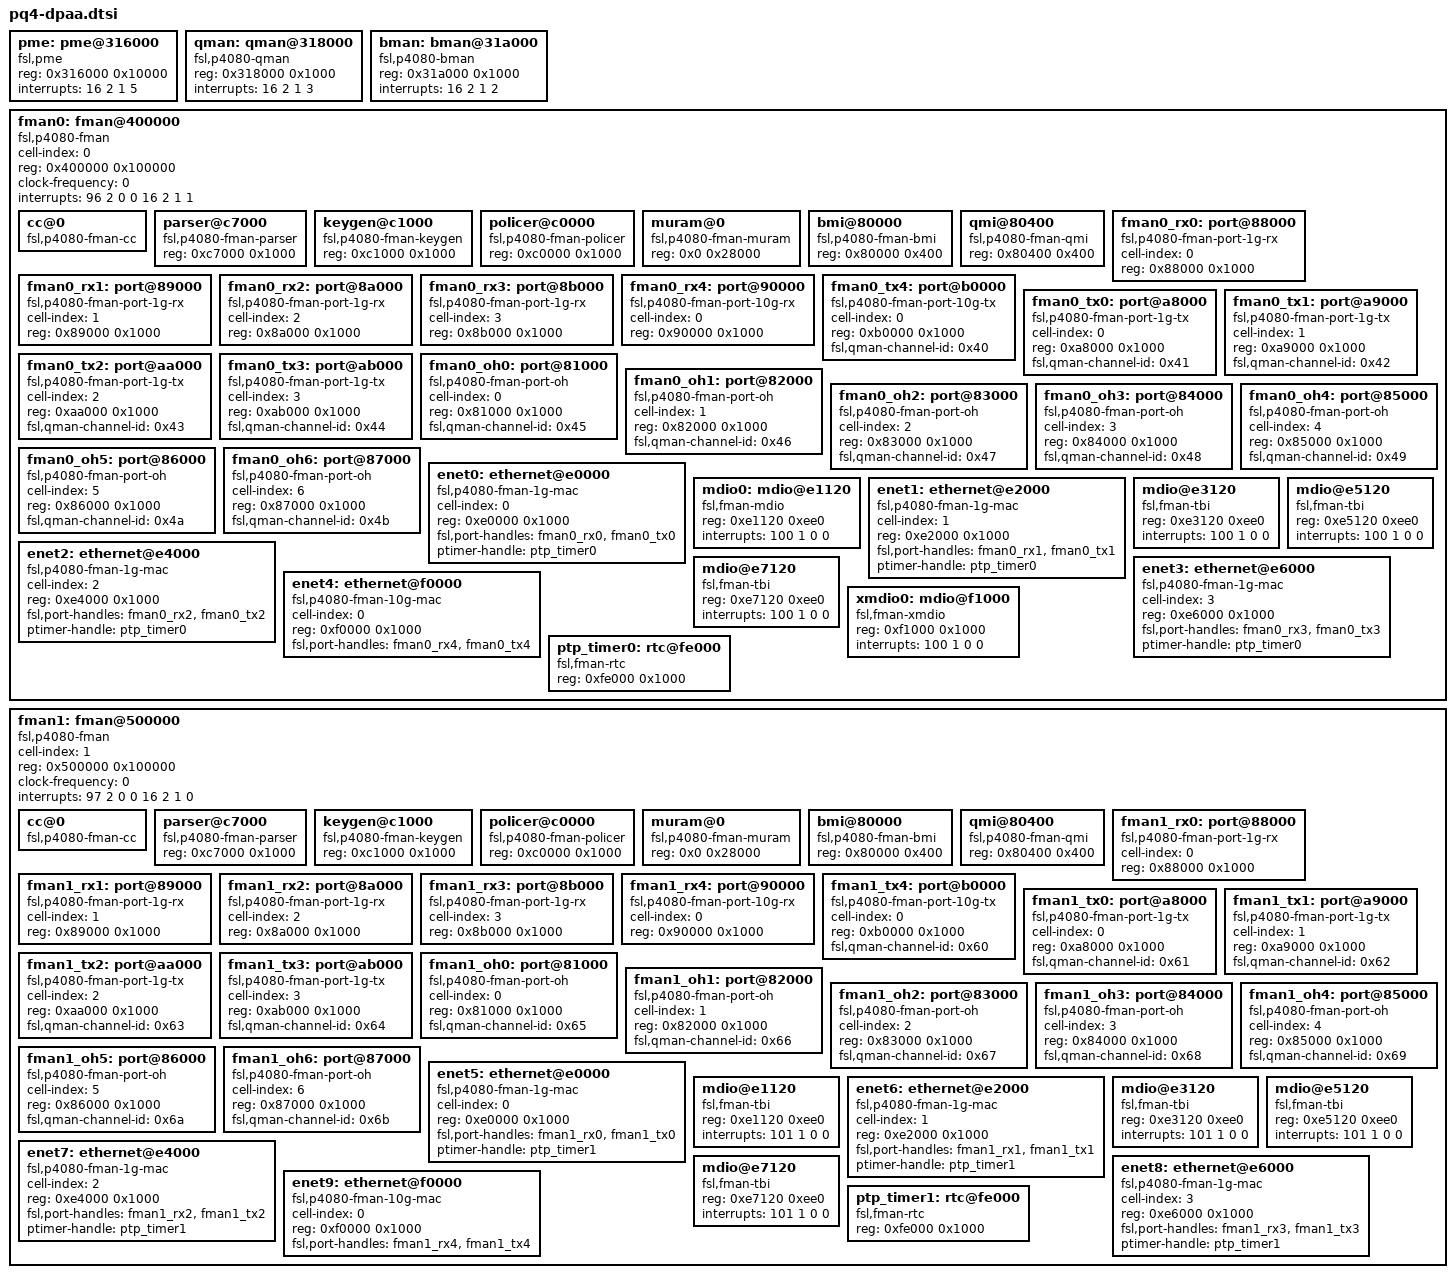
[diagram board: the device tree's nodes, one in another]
/*
 * P4 pme, qman, bman and famn Device Tree Source
 *
 * Copyright 2009-2011 Freescale Semiconductor Inc.
 *
 * Redistribution and use in source and binary forms, with or without
 * modification, are permitted provided that the following conditions are met:
 *     * Redistributions of source code must retain the above copyright
 *       notice, this list of conditions and the following disclaimer.
 *     * Redistributions in binary form must reproduce the above copyright
 *       notice, this list of conditions and the following disclaimer in the
 *       documentation and/or other materials provided with the distribution.
 *     * Neither the name of Freescale Semiconductor nor the
 *       names of its contributors may be used to endorse or promote products
 *       derived from this software without specific prior written permission.
 *
 *
 * ALTERNATIVELY, this software may be distributed under the terms of the
 * GNU General Public License ("GPL") as published by the Free Software
 * Foundation, either version 2 of that License or (at your option) any
 * later version.
 *
 * THIS SOFTWARE IS PROVIDED BY Freescale Semiconductor ``AS IS'' AND ANY
 * EXPRESS OR IMPLIED WARRANTIES, INCLUDING, BUT NOT LIMITED TO, THE IMPLIED
 * WARRANTIES OF MERCHANTABILITY AND FITNESS FOR A PARTICULAR PURPOSE ARE
 * DISCLAIMED. IN NO EVENT SHALL Freescale Semiconductor BE LIABLE FOR ANY
 * DIRECT, INDIRECT, INCIDENTAL, SPECIAL, EXEMPLARY, OR CONSEQUENTIAL DAMAGES
 * (INCLUDING, BUT NOT LIMITED TO, PROCUREMENT OF SUBSTITUTE GOODS OR SERVICES;
 * LOSS OF USE, DATA, OR PROFITS; OR BUSINESS INTERRUPTION) HOWEVER CAUSED AND
 * ON ANY THEORY OF LIABILITY, WHETHER IN CONTRACT, STRICT LIABILITY, OR TORT
 * (INCLUDING NEGLIGENCE OR OTHERWISE) ARISING IN ANY WAY OUT OF THE USE OF THIS
 * SOFTWARE, EVEN IF ADVISED OF THE POSSIBILITY OF SUCH DAMAGE.
 */

pme: pme@316000 {
	compatible = "fsl,pme";
	reg = <0x316000 0x10000>;
	/* fsl,pme-pdsr = <0x0 0x23000000 0x0 0x01000000>; */
	/* fsl,pme-sre = <0x0 0x24000000 0x0 0x00a00000>; */
	interrupts = <16 2 1 5>;
};

qman: qman@318000 {
	compatible = "fsl,p4080-qman", "fsl,qman";
	reg = <0x318000 0x1000>;
	interrupts = <16 2 1 3>;
	/* Commented out, use default allocation */
	/* fsl,qman-fqd = <0x0 0x20000000 0x0 0x01000000>; */
	/* fsl,qman-pfdr = <0x0 0x21000000 0x0 0x01000000>; */
};

bman: bman@31a000 {
	compatible = "fsl,p4080-bman", "fsl,bman";
	reg = <0x31a000 0x1000>;
	interrupts = <16 2 1 2>;
	/* Same as fsl,qman-*, use default allocation */
	/* fsl,bman-fbpr = <0x0 0x22000000 0x0 0x01000000>; */
};

fman0: fman@400000 {
	#address-cells = <1>;
	#size-cells = <1>;
	cell-index = <0>;
	compatible = "fsl,p4080-fman", "fsl,fman", "simple-bus";
	ranges = <0 0x400000 0x100000>;
	reg = <0x400000 0x100000>;
	clock-frequency = <0>;
	interrupts = <
		96 2 0 0
		16 2 1 1>;

	cc@0 {
		compatible = "fsl,p4080-fman-cc", "fsl,fman-cc";
	};

	parser@c7000 {
		compatible = "fsl,p4080-fman-parser", "fsl,fman-parser";
		reg = <0xc7000 0x1000>;
	};

	keygen@c1000 {
		compatible = "fsl,p4080-fman-keygen", "fsl,fman-keygen";
		reg = <0xc1000 0x1000>;
	};

	policer@c0000 {
		compatible = "fsl,p4080-fman-policer", "fsl,fman-policer";
		reg = <0xc0000 0x1000>;
	};

	muram@0 {
		compatible = "fsl,p4080-fman-muram", "fsl,fman-muram";
		reg = <0x0 0x28000>;
	};

	bmi@80000 {
		compatible = "fsl,p4080-fman-bmi", "fsl,fman-bmi";
		reg = <0x80000 0x400>;
	};

	qmi@80400 {
		compatible = "fsl,p4080-fman-qmi", "fsl,fman-qmi";
		reg = <0x80400 0x400>;
	};

	fman0_rx0: port@88000 {
		cell-index = <0>;
		compatible = "fsl,p4080-fman-port-1g-rx", "fsl,fman-port-1g-rx";
		reg = <0x88000 0x1000>;
	};
	fman0_rx1: port@89000 {
		cell-index = <1>;
		compatible = "fsl,p4080-fman-port-1g-rx", "fsl,fman-port-1g-rx";
		reg = <0x89000 0x1000>;
	};
	fman0_rx2: port@8a000 {
		cell-index = <2>;
		compatible = "fsl,p4080-fman-port-1g-rx", "fsl,fman-port-1g-rx";
		reg = <0x8a000 0x1000>;
	};
	fman0_rx3: port@8b000 {
		cell-index = <3>;
		compatible = "fsl,p4080-fman-port-1g-rx", "fsl,fman-port-1g-rx";
		reg = <0x8b000 0x1000>;
	};
	fman0_rx4: port@90000 {
		cell-index = <0>;
		compatible = "fsl,p4080-fman-port-10g-rx", "fsl,fman-port-10g-rx";
		reg = <0x90000 0x1000>;
	};

	fman0_tx4: port@b0000 {
		cell-index = <0>;
		compatible = "fsl,p4080-fman-port-10g-tx", "fsl,fman-port-10g-tx";
		reg = <0xb0000 0x1000>;
		fsl,qman-channel-id = <0x40>;
	};
	fman0_tx0: port@a8000 {
		cell-index = <0>;
		compatible = "fsl,p4080-fman-port-1g-tx", "fsl,fman-port-1g-tx";
		reg = <0xa8000 0x1000>;
		fsl,qman-channel-id = <0x41>;
	};
	fman0_tx1: port@a9000 {
		cell-index = <1>;
		compatible = "fsl,p4080-fman-port-1g-tx", "fsl,fman-port-1g-tx";
		reg = <0xa9000 0x1000>;
		fsl,qman-channel-id = <0x42>;
	};
	fman0_tx2: port@aa000 {
		cell-index = <2>;
		compatible = "fsl,p4080-fman-port-1g-tx", "fsl,fman-port-1g-tx";
		reg = <0xaa000 0x1000>;
		fsl,qman-channel-id = <0x43>;
	};
	fman0_tx3: port@ab000 {
		cell-index = <3>;
		compatible = "fsl,p4080-fman-port-1g-tx", "fsl,fman-port-1g-tx";
		reg = <0xab000 0x1000>;
		fsl,qman-channel-id = <0x44>;
	};

	fman0_oh0: port@81000 {
		cell-index = <0>;
		compatible = "fsl,p4080-fman-port-oh", "fsl,fman-port-oh";
		reg = <0x81000 0x1000>;
		fsl,qman-channel-id = <0x45>;
	};
	fman0_oh1: port@82000 {
		cell-index = <1>;
		compatible = "fsl,p4080-fman-port-oh", "fsl,fman-port-oh";
		reg = <0x82000 0x1000>;
		fsl,qman-channel-id = <0x46>;
	};
	fman0_oh2: port@83000 {
		cell-index = <2>;
		compatible = "fsl,p4080-fman-port-oh", "fsl,fman-port-oh";
		reg = <0x83000 0x1000>;
		fsl,qman-channel-id = <0x47>;
	};
	fman0_oh3: port@84000 {
		cell-index = <3>;
		compatible = "fsl,p4080-fman-port-oh", "fsl,fman-port-oh";
		reg = <0x84000 0x1000>;
		fsl,qman-channel-id = <0x48>;
	};
	fman0_oh4: port@85000 {
		cell-index = <4>;
		compatible = "fsl,p4080-fman-port-oh", "fsl,fman-port-oh";
		reg = <0x85000 0x1000>;
		fsl,qman-channel-id = <0x49>;
	};
	fman0_oh5: port@86000 {
		cell-index = <5>;
		compatible = "fsl,p4080-fman-port-oh", "fsl,fman-port-oh";
		reg = <0x86000 0x1000>;
		fsl,qman-channel-id = <0x4a>;
	};
	fman0_oh6: port@87000 {
		cell-index = <6>;
		compatible = "fsl,p4080-fman-port-oh", "fsl,fman-port-oh";
		reg = <0x87000 0x1000>;
		fsl,qman-channel-id = <0x4b>;
	};

	enet0: ethernet@e0000 {
		cell-index = <0>;
		compatible = "fsl,p4080-fman-1g-mac", "fsl,fman-1g-mac";
		reg = <0xe0000 0x1000>;
		fsl,port-handles = <&fman0_rx0 &fman0_tx0>;
		ptimer-handle = <&ptp_timer0>;
	};

	mdio0: mdio@e1120 {
		#address-cells = <1>;
		#size-cells = <0>;
		compatible = "fsl,fman-mdio";
		reg = <0xe1120 0xee0>;
		interrupts = <100 1 0 0>;
	};

	enet1: ethernet@e2000 {
		cell-index = <1>;
		compatible = "fsl,p4080-fman-1g-mac", "fsl,fman-1g-mac";
		reg = <0xe2000 0x1000>;
		fsl,port-handles = <&fman0_rx1 &fman0_tx1>;
		ptimer-handle = <&ptp_timer0>;
	};

	mdio@e3120 {
		#address-cells = <1>;
		#size-cells = <0>;
		compatible = "fsl,fman-tbi";
		reg = <0xe3120 0xee0>;
		interrupts = <100 1 0 0>;
	};

	enet2: ethernet@e4000 {
		cell-index = <2>;
		compatible = "fsl,p4080-fman-1g-mac", "fsl,fman-1g-mac";
		reg = <0xe4000 0x1000>;
		fsl,port-handles = <&fman0_rx2 &fman0_tx2>;
		ptimer-handle = <&ptp_timer0>;
	};

	mdio@e5120 {
		#address-cells = <1>;
		#size-cells = <0>;
		compatible = "fsl,fman-tbi";
		reg = <0xe5120 0xee0>;
		interrupts = <100 1 0 0>;
	};

	enet3: ethernet@e6000 {
		cell-index = <3>;
		compatible = "fsl,p4080-fman-1g-mac", "fsl,fman-1g-mac";
		reg = <0xe6000 0x1000>;
		fsl,port-handles = <&fman0_rx3 &fman0_tx3>;
		ptimer-handle = <&ptp_timer0>;
	};

	mdio@e7120 {
		#address-cells = <1>;
		#size-cells = <0>;
		compatible = "fsl,fman-tbi";
		reg = <0xe7120 0xee0>;
		interrupts = <100 1 0 0>;
	};
	enet4: ethernet@f0000 {
		cell-index = <0>;
		compatible = "fsl,p4080-fman-10g-mac", "fsl,fman-10g-mac";
		reg = <0xf0000 0x1000>;
		fsl,port-handles = <&fman0_rx4 &fman0_tx4>;
	};

	xmdio0: mdio@f1000 {
		#address-cells = <1>;
		#size-cells = <0>;
		compatible = "fsl,fman-xmdio";
		reg = <0xf1000 0x1000>;
		interrupts = <100 1 0 0>;
	};

	ptp_timer0: rtc@fe000 {
		compatible = "fsl,fman-rtc";
		reg = <0xfe000 0x1000>;
	};
};

fman1: fman@500000 {
	#address-cells = <1>;
	#size-cells = <1>;
	cell-index = <1>;
	compatible = "fsl,p4080-fman", "fsl,fman", "simple-bus";
	ranges = <0 0x500000 0x100000>;
	reg = <0x500000 0x100000>;
	clock-frequency = <0>;
	interrupts = <
		97 2 0 0
		16 2 1 0>;

	cc@0 {
		compatible = "fsl,p4080-fman-cc", "fsl,fman-cc";
	};

	parser@c7000 {
		compatible = "fsl,p4080-fman-parser", "fsl,fman-parser";
		reg = <0xc7000 0x1000>;
	};

	keygen@c1000 {
		compatible = "fsl,p4080-fman-keygen", "fsl,fman-keygen";
		reg = <0xc1000 0x1000>;
	};

	policer@c0000 {
		compatible = "fsl,p4080-fman-policer", "fsl,fman-policer";
		reg = <0xc0000 0x1000>;
	};

	muram@0 {
		compatible = "fsl,p4080-fman-muram", "fsl,fman-muram";
		reg = <0x0 0x28000>;
	};

	bmi@80000 {
		compatible = "fsl,p4080-fman-bmi", "fsl,fman-bmi";
		reg = <0x80000 0x400>;
	};

	qmi@80400 {
		compatible = "fsl,p4080-fman-qmi", "fsl,fman-qmi";
		reg = <0x80400 0x400>;
	};

	fman1_rx0: port@88000 {
		cell-index = <0>;
		compatible = "fsl,p4080-fman-port-1g-rx", "fsl,fman-port-1g-rx";
		reg = <0x88000 0x1000>;
	};
	fman1_rx1: port@89000 {
		cell-index = <1>;
		compatible = "fsl,p4080-fman-port-1g-rx", "fsl,fman-port-1g-rx";
		reg = <0x89000 0x1000>;
	};
	fman1_rx2: port@8a000 {
		cell-index = <2>;
		compatible = "fsl,p4080-fman-port-1g-rx", "fsl,fman-port-1g-rx";
		reg = <0x8a000 0x1000>;
	};
	fman1_rx3: port@8b000 {
		cell-index = <3>;
		compatible = "fsl,p4080-fman-port-1g-rx", "fsl,fman-port-1g-rx";
		reg = <0x8b000 0x1000>;
	};
	fman1_rx4: port@90000 {
		cell-index = <0>;
		compatible = "fsl,p4080-fman-port-10g-rx", "fsl,fman-port-10g-rx";
		reg = <0x90000 0x1000>;
	};

	fman1_tx4: port@b0000 {
		cell-index = <0>;
		compatible = "fsl,p4080-fman-port-10g-tx", "fsl,fman-port-10g-tx";
		reg = <0xb0000 0x1000>;
		fsl,qman-channel-id = <0x60>;
	};
	fman1_tx0: port@a8000 {
		cell-index = <0>;
		compatible = "fsl,p4080-fman-port-1g-tx", "fsl,fman-port-1g-tx";
		reg = <0xa8000 0x1000>;
		fsl,qman-channel-id = <0x61>;
	};
	fman1_tx1: port@a9000 {
		cell-index = <1>;
		compatible = "fsl,p4080-fman-port-1g-tx", "fsl,fman-port-1g-tx";
		reg = <0xa9000 0x1000>;
		fsl,qman-channel-id = <0x62>;
	};
	fman1_tx2: port@aa000 {
		cell-index = <2>;
		compatible = "fsl,p4080-fman-port-1g-tx", "fsl,fman-port-1g-tx";
		reg = <0xaa000 0x1000>;
		fsl,qman-channel-id = <0x63>;
	};
	fman1_tx3: port@ab000 {
		cell-index = <3>;
		compatible = "fsl,p4080-fman-port-1g-tx", "fsl,fman-port-1g-tx";
		reg = <0xab000 0x1000>;
		fsl,qman-channel-id = <0x64>;
	};

	fman1_oh0: port@81000 {
		cell-index = <0>;
		compatible = "fsl,p4080-fman-port-oh", "fsl,fman-port-oh";
		reg = <0x81000 0x1000>;
		fsl,qman-channel-id = <0x65>;
	};
	fman1_oh1: port@82000 {
		cell-index = <1>;
		compatible = "fsl,p4080-fman-port-oh", "fsl,fman-port-oh";
		reg = <0x82000 0x1000>;
		fsl,qman-channel-id = <0x66>;
	};
	fman1_oh2: port@83000 {
		cell-index = <2>;
		compatible = "fsl,p4080-fman-port-oh", "fsl,fman-port-oh";
		reg = <0x83000 0x1000>;
		fsl,qman-channel-id = <0x67>;
	};
	fman1_oh3: port@84000 {
		cell-index = <3>;
		compatible = "fsl,p4080-fman-port-oh", "fsl,fman-port-oh";
		reg = <0x84000 0x1000>;
		fsl,qman-channel-id = <0x68>;
	};
	fman1_oh4: port@85000 {
		cell-index = <4>;
		compatible = "fsl,p4080-fman-port-oh", "fsl,fman-port-oh";
		reg = <0x85000 0x1000>;
		fsl,qman-channel-id = <0x69>;
	};
	fman1_oh5: port@86000 {
		cell-index = <5>;
		compatible = "fsl,p4080-fman-port-oh", "fsl,fman-port-oh";
		reg = <0x86000 0x1000>;
		fsl,qman-channel-id = <0x6a>;
	};
	fman1_oh6: port@87000 {
		cell-index = <6>;
		compatible = "fsl,p4080-fman-port-oh", "fsl,fman-port-oh";
		reg = <0x87000 0x1000>;
		fsl,qman-channel-id = <0x6b>;
	};

	enet5: ethernet@e0000 {
		cell-index = <0>;
		compatible = "fsl,p4080-fman-1g-mac", "fsl,fman-1g-mac";
		reg = <0xe0000 0x1000>;
		fsl,port-handles = <&fman1_rx0 &fman1_tx0>;
		ptimer-handle = <&ptp_timer1>;
	};
	mdio@e1120 {
		#address-cells = <1>;
		#size-cells = <0>;
		compatible = "fsl,fman-tbi";
		reg = <0xe1120 0xee0>;
		interrupts = <101 1 0 0>;
	};

	enet6: ethernet@e2000 {
		cell-index = <1>;
		compatible = "fsl,p4080-fman-1g-mac", "fsl,fman-1g-mac";
		reg = <0xe2000 0x1000>;
		fsl,port-handles = <&fman1_rx1 &fman1_tx1>;
		ptimer-handle = <&ptp_timer1>;
	};

	mdio@e3120 {
		#address-cells = <1>;
		#size-cells = <0>;
		compatible = "fsl,fman-tbi";
		reg = <0xe3120 0xee0>;
		interrupts = <101 1 0 0>;
	};

	enet7: ethernet@e4000 {
		cell-index = <2>;
		compatible = "fsl,p4080-fman-1g-mac", "fsl,fman-1g-mac";
		reg = <0xe4000 0x1000>;
		fsl,port-handles = <&fman1_rx2 &fman1_tx2>;
		ptimer-handle = <&ptp_timer1>;
	};

	mdio@e5120 {
		#address-cells = <1>;
		#size-cells = <0>;
		compatible = "fsl,fman-tbi";
		reg = <0xe5120 0xee0>;
		interrupts = <101 1 0 0>;
	};

	enet8: ethernet@e6000 {
		cell-index = <3>;
		compatible = "fsl,p4080-fman-1g-mac", "fsl,fman-1g-mac";
		reg = <0xe6000 0x1000>;
		fsl,port-handles = <&fman1_rx3 &fman1_tx3>;
		ptimer-handle = <&ptp_timer1>;
	};

	mdio@e7120 {
		#address-cells = <1>;
		#size-cells = <0>;
		compatible = "fsl,fman-tbi";
		reg = <0xe7120 0xee0>;
		interrupts = <101 1 0 0>;
	};

	enet9: ethernet@f0000 {
		cell-index = <0>;
		compatible = "fsl,p4080-fman-10g-mac", "fsl,fman-10g-mac";
		reg = <0xf0000 0x1000>;
		fsl,port-handles = <&fman1_rx4 &fman1_tx4>;
	};

	ptp_timer1: rtc@fe000 {
		compatible = "fsl,fman-rtc";
		reg = <0xfe000 0x1000>;
	};
};
